# STM32H7B3x register map
File version: 2.2
CPU: CM7 r0p1, little endian, MPU, FPU, 4 interrupt priority bits
Registers are 32-bit, read-write, reset 0x0 unless marked. A register's access mark holds for its fields unless they carry their own. Offsets are from the block's base; [hi:lo] are bit positions.

## SPI1 — Serial peripheral interface
Base 0x40013000
Same registers: SPI2 0x40003800, SPI3 0x40003C00, SPI4 0x40013400, SPI5 0x40015000, SPI6 0x58001400
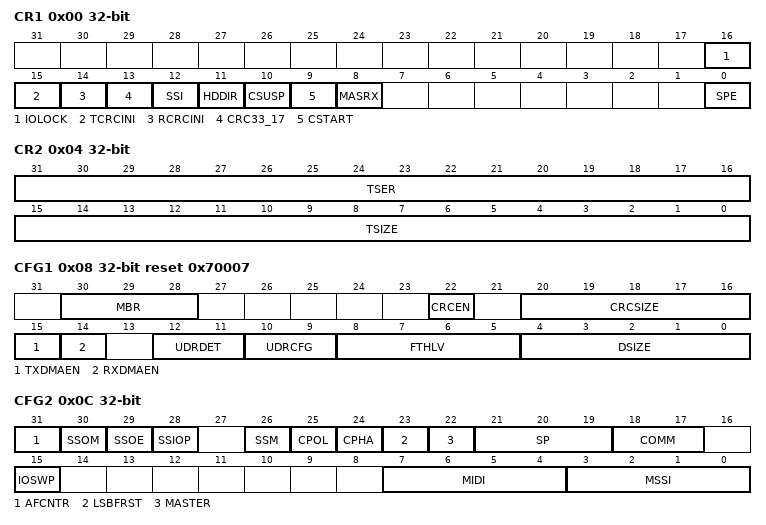
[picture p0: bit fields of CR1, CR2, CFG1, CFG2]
0x00 CR1 access per field — control register 1
  [16] IOLOCK rw — Locking the AF configuration of associated IOs
    0=Unlocked (IO configuration unlocked); 1=Locked (IO configuration locked)
  [15] TCRCINI rw — CRC calculation initialization pattern control for transmitter
    0=All zeros TX CRC initialization pattern; 1=All ones TX CRC initialization pattern
  [14] RCRCINI rw — CRC calculation initialization pattern control for receiver
    0=All zeros RX CRC initialization pattern; 1=All ones RX CRC initialization pattern
  [13] CRC33_17 rw — 32-bit CRC polynomial configuration
    0=Disabled (Full size (33/17 bit) CRC polynomial is not used); 1=Enabled (Full size (33/17 bit) CRC polynomial is used)
  [12] SSI rw — Internal SS signal input level
    0=SlaveSelected (0 is forced onto the SS signal and the I/O value of the SS pin is ignored); 1=SlaveNotSelected (1 is forced onto the SS signal and the I/O value of the SS pin is ignored)
  [11] HDDIR rw — Rx/Tx direction at Half-duplex mode
    0=Receiver in half duplex mode; 1=Transmitter in half duplex mode
  [10] CSUSP wo — Master SUSPend request
    on write: 0=NotRequested (Do not request master suspend); 1=Requested (Request master suspend)
  [9] CSTART rw — Master transfer start
    0=NotStarted (Do not start master transfer); 1=Started (Start master transfer)
  [8] MASRX rw — Master automatic SUSP in Receive mode
    0=Disabled (Automatic suspend in master receive-only mode disabled); 1=Enabled (Automatic suspend in master receive-only mode enabled)
  [0] SPE rw — Serial Peripheral Enable
    0=Disabled (Peripheral disabled); 1=Enabled (Peripheral enabled)
0x04 CR2 — control register 2
  [31:16] TSER — Number of data transfer extension to be reload into TSIZE just when a previous
  [15:0] TSIZE — Number of data at current transfer
0x08 CFG1 reset 0x70007 — configuration register 1
  [30:28] MBR — Master baud rate
    0=Div2 (f_spi_ker_ck / 2); 1=Div4 (f_spi_ker_ck / 4); 2=Div8 (f_spi_ker_ck / 8); 3=Div16 (f_spi_ker_ck / 16); 4=Div32 (f_spi_ker_ck / 32); 5=Div64 (f_spi_ker_ck / 64); 6=Div128 (f_spi_ker_ck / 128); 7=Div256 (f_spi_ker_ck / 256)
  [22] CRCEN — Hardware CRC computation enable
    0=Disabled (CRC calculation disabled); 1=Enabled (CRC calculation enabled)
  [20:16] CRCSIZE — Length of CRC frame to be transacted and compared
  [15] TXDMAEN — Tx DMA stream enable
    0=Disabled (Tx buffer DMA disabled); 1=Enabled (Tx buffer DMA enabled)
  [14] RXDMAEN — Rx DMA stream enable
    0=Disabled (Rx buffer DMA disabled); 1=Enabled (Rx buffer DMA enabled)
  [12:11] UDRDET — Detection of underrun condition at slave transmitter
    0=StartOfFrame (Underrun is detected at begin of data frame); 1=EndOfFrame (Underrun is detected at end of last data frame); 2=StartOfSlaveSelect (Underrun is detected at begin of active SS signal)
  [10:9] UDRCFG — Behavior of slave transmitter at underrun condition
    0=Constant (Slave sends a constant underrun pattern); 1=RepeatReceived (Slave repeats last received data frame from master); 2=RepeatTransmitted (Slave repeats last transmitted data frame)
  [8:5] FTHLV — threshold level
    0=OneFrame (1 frame); 1=TwoFrames (2 frames); 2=ThreeFrames (3 frames); 3=FourFrames (4 frames); 4=FiveFrames (5 frames); 5=SixFrames (6 frames); 6=SevenFrames (7 frames); 7=EightFrames (8 frames); 8=NineFrames (9 frames); 9=TenFrames (10 frames); 10=ElevenFrames (11 frames); 11=TwelveFrames (12 frames); 12=ThirteenFrames (13 frames); 13=FourteenFrames (14 frames); 14=FifteenFrames (15 frames); 15=SixteenFrames (16 frames)
  [4:0] DSIZE — Number of bits in at single SPI data frame
0x0C CFG2 — configuration register 2
  [31] AFCNTR — Alternate function GPIOs control
    0=NotControlled (Peripheral takes no control of GPIOs while disabled); 1=Controlled (Peripheral controls GPIOs while disabled)
  [30] SSOM — SS output management in master mode
    0=Asserted (SS is asserted until data transfer complete); 1=NotAsserted (Data frames interleaved with SS not asserted during MIDI)
  [29] SSOE — SS output enable
    0=Disabled (SS output is disabled in master mode); 1=Enabled (SS output is enabled in master mode)
  [28] SSIOP — SS input/output polarity
    0=ActiveLow (Low level is active for SS signal); 1=ActiveHigh (High level is active for SS signal)
  [26] SSM — Software management of SS signal input
    0=Disabled (Software slave management disabled); 1=Enabled (Software slave management enabled)
  [25] CPOL — Clock polarity
    0=IdleLow (CK to 0 when idle); 1=IdleHigh (CK to 1 when idle)
  [24] CPHA — Clock phase
    0=FirstEdge (The first clock transition is the first data capture edge); 1=SecondEdge (The second clock transition is the first data capture edge)
  [23] LSBFRST — Data frame format
    0=MSBFirst (Data is transmitted/received with the MSB first); 1=LSBFirst (Data is transmitted/received with the LSB first)
  [22] MASTER — SPI Master
    0=Slave configuration; 1=Master configuration
  [21:19] SP — Serial Protocol
    0=Motorola SPI protocol; 1=TI (TI SPI protocol)
  [18:17] COMM — SPI Communication Mode
    0=FullDuplex; 1=Transmitter (Simplex transmitter only); 2=Receiver (Simplex receiver only); 3=HalfDuplex
  [15] IOSWP — Swap functionality of MISO and MOSI pins
    0=Disabled (MISO and MOSI not swapped); 1=Enabled (MISO and MOSI swapped)
  [7:4] MIDI — Master Inter-Data Idleness
  [3:0] MSSI — Master SS Idleness
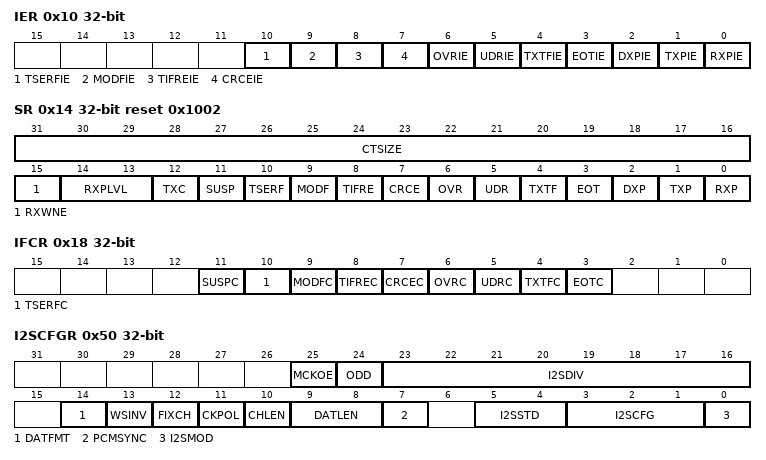
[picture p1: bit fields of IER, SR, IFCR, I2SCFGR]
0x10 IER — Interrupt Enable Register
  [10] TSERFIE — Additional number of transactions reload interrupt enable
    0=Masked (TSER loaded interrupt masked); 1=NotMasked (TSER loaded interrupt not masked)
  [9] MODFIE — Mode Fault interrupt enable
    0=Masked (Mode fault interrupt masked); 1=NotMasked (Mode fault interrupt not masked)
  [8] TIFREIE — TIFRE interrupt enable
    0=Masked (TI frame format error interrupt masked); 1=NotMasked (TI frame format error interrupt not masked)
  [7] CRCEIE — CRC Interrupt enable
    0=Masked (CRC error interrupt masked); 1=NotMasked (CRC error interrupt not masked)
  [6] OVRIE — OVR interrupt enable
    0=Masked (Overrun interrupt masked); 1=NotMasked (Overrun interrupt not masked)
  [5] UDRIE — UDR interrupt enable
    0=Masked (Underrun interrupt masked); 1=NotMasked (Underrun interrupt not masked)
  [4] TXTFIE — TXTFIE interrupt enable
    0=Masked (Transmission transfer filled interrupt masked); 1=NotMasked (Transmission transfer filled interrupt not masked)
  [3] EOTIE — EOT, SUSP and TXC interrupt enable
    0=Masked (End-of-transfer interrupt masked); 1=NotMasked (End-of-transfer interrupt not masked)
  [2] DXPIE — DXP interrupt enabled
    0=Masked (Duplex transfer complete interrupt masked); 1=NotMasked (Duplex transfer complete interrupt not masked)
  [1] TXPIE — TXP interrupt enable
    0=Masked (TX space available interrupt masked); 1=NotMasked (TX space available interrupt not masked)
  [0] RXPIE — RXP Interrupt Enable
    0=Masked (RX data available interrupt masked); 1=NotMasked (RX data available interrupt not masked)
0x14 SR ro reset 0x1002 — Status Register
  [31:16] CTSIZE — Number of data frames remaining in current TSIZE session
  [15] RXWNE — RxFIFO Word Not Empty
    on read: 0=Less than 32-bit data frame received; 1=At least 32-bit data frame received
  [14:13] RXPLVL — RxFIFO Packing LeVeL
    on read: 0=Zero frames beyond packing ratio available; 1=One frame beyond packing ratio available; 2=TwoFrames (Two frame beyond packing ratio available); 3=ThreeFrames (Three frame beyond packing ratio available)
  [12] TXC — TxFIFO transmission complete
    on read: 0=Ongoing (Transmission ongoing); 1=Completed (Transmission completed)
  [11] SUSP — SUSPend
    on read: 0=NotSuspended (Master not suspended); 1=Suspended (Master suspended)
  [10] TSERF — Additional number of SPI data to be transacted was reload
    on read: 0=NotLoaded (Additional number of SPI data to be transacted not yet loaded); 1=Loaded (Additional number of SPI data to be transacted was reloaded)
  [9] MODF — Mode Fault
    on read: 0=NoFault (No mode fault detected); 1=Fault (Mode fault detected)
  [8] TIFRE — TI frame format error
    on read: 0=NoError (TI frame format error detected); 1=Error (TI frame format error detected)
  [7] CRCE — CRC Error
    on read: 0=NoError (No CRC error detected); 1=Error (CRC error detected)
  [6] OVR — Overrun
    on read: 0=No overrun occurred; 1=Overrun occurred
  [5] UDR — Underrun at slave transmission mode
    on read: 0=No underrun occurred; 1=Underrun occurred
  [4] TXTF — Transmission Transfer Filled
    on read: 0=NotCompleted (Transmission buffer incomplete); 1=Completed (Transmission buffer filled with at least one transfer)
  [3] EOT — End Of Transfer
    on read: 0=NotCompleted (Transfer ongoing or not started); 1=Completed (Transfer complete)
  [2] DXP — Duplex Packet
    on read: 0=Unavailable (Duplex packet unavailable: no space for transmission and/or no data received); 1=Available (Duplex packet available: space for transmission and data received)
  [1] TXP — Tx-Packet space available
    on read: 0=Full (Tx buffer full); 1=NotFull (Tx buffer not full)
  [0] RXP — Rx-Packet available
    on read: 0=Empty (Rx buffer empty); 1=NotEmpty (Rx buffer not empty)
0x18 IFCR wo — Interrupt/Status Flags Clear Register
  [all] fields
    on write: 1=Clear interrupt flag
  [11] SUSPC — SUSPend flag clear
  [10] TSERFC — TSERFC flag clear
  [9] MODFC — Mode Fault flag clear
  [8] TIFREC — TI frame format error flag clear
  [7] CRCEC — CRC Error flag clear
  [6] OVRC — Overrun flag clear
  [5] UDRC — Underrun flag clear
  [4] TXTFC — Transmission Transfer Filled flag clear
  [3] EOTC — End Of Transfer flag clear
0x20 TXDR wo — Transmit Data Register
  [31:0] TXDR — Transmit data register
0x30 RXDR ro — Receive Data Register
  [31:0] RXDR — Receive data register
0x40 CRCPOLY reset 0x107 — Polynomial Register
  [31:0] CRCPOLY — CRC polynomial register
0x44 TXCRC — Transmitter CRC Register
  [31:0] TXCRC — CRC register for transmitter
0x48 RXCRC — Receiver CRC Register
  [31:0] RXCRC — CRC register for receiver
0x4C UDRDR — Underrun Data Register
  [31:0] UDRDR — Data at slave underrun condition
0x50 I2SCFGR — configuration register
  [25] MCKOE — Master clock output enable
    0=Disabled (Master clock output disabled); 1=Enabled (Master clock output enabled)
  [24] ODD — Odd factor for the prescaler
    0=Even (Real divider value is I2SDIV*2); 1=Odd (Real divider value is I2SDIV*2 + 1)
  [23:16] I2SDIV — I2S linear prescaler
  [14] DATFMT — Data format
    0=RightAligned (The data inside RXDR and TXDR are right aligned); 1=LeftAligned (The data inside RXDR and TXDR are left aligned)
  [13] WSINV — Fixed channel length in SLAVE
    0=Disabled (Word select inversion disabled); 1=Enabled (Word select inversion enabled)
  [12] FIXCH — Word select inversion
    0=NotFixed (The channel length in slave mode is different from 16 or 32 bits (CHLEN not taken into account)); 1=Fixed (The channel length in slave mode is supposed to be 16 or 32 bits (according to CHLEN))
  [11] CKPOL — Serial audio clock polarity
    0=SampleOnRising (Signals are sampled on rising and changed on falling clock edges); 1=SampleOnFalling (Signals are sampled on falling and changed on rising clock edges)
  [10] CHLEN — Channel length (number of bits per audio channel)
    0=Bits16 (16 bit per channel); 1=Bits32 (32 bit per channel)
  [9:8] DATLEN — Data length to be transferred
    0=Bits16 (16 bit data length); 1=Bits24 (24 bit data length); 2=Bits32 (32 bit data length)
  [7] PCMSYNC — PCM frame synchronization
    0=Short PCM frame synchronization; 1=Long PCM frame synchronization
  [5:4] I2SSTD — I2S standard selection
    0=Philips (I2S Philips standard); 1=LeftAligned (MSB/left justified standard); 2=RightAligned (LSB/right justified standard); 3=PCM (PCM standard)
  [3:1] I2SCFG — I2S configuration mode
    0=SlaveTransmit; 1=SlaveReceive (Slave, recteive); 2=MasterTransmit; 3=MasterReceive; 4=SlaveFullDuplex; 5=MasterFullDuplex
  [0] I2SMOD — I2S mode selection
    0=SPI (SPI mode selected); 1=I2S (I2S/PCM mode selected)
